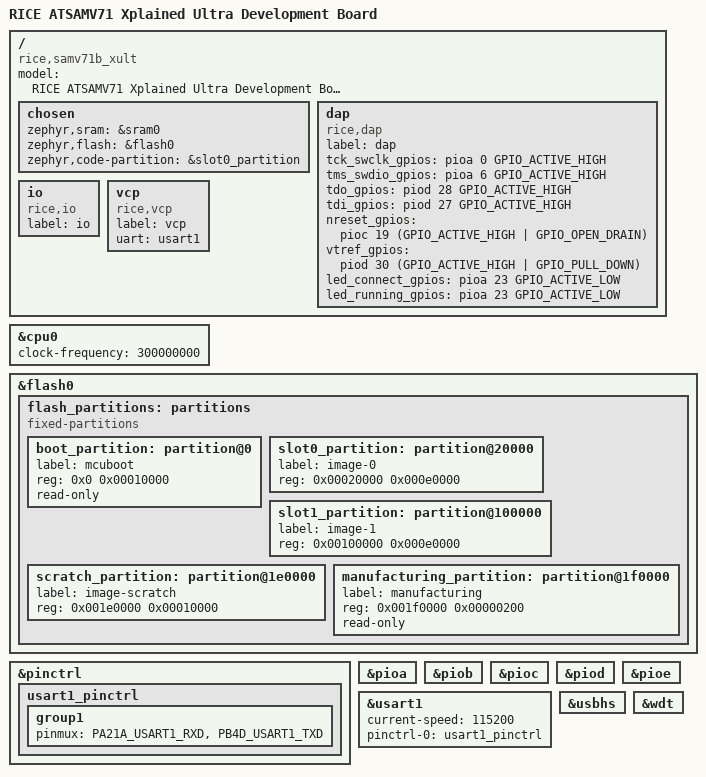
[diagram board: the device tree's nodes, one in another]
/dts-v1/;

#include <atmel/samv71q21b.dtsi>
#include <dt-bindings/pinctrl/samv71q-pinctrl.h>

/ {
    model = "RICE ATSAMV71 Xplained Ultra Development Board";
    compatible = "rice,samv71b_xult", "atmel,samv71q21b", "atmel,samv71b";

    chosen {
		zephyr,sram = &sram0;
		zephyr,flash = &flash0;
		zephyr,code-partition = &slot0_partition;
	};

    dap: dap {
        label = "dap";
        compatible = "rice,dap";

		tck_swclk_gpios = <&pioa 0 GPIO_ACTIVE_HIGH>;
		tms_swdio_gpios = <&pioa 6 GPIO_ACTIVE_HIGH>;
		tdo_gpios = <&piod 28 GPIO_ACTIVE_HIGH>;
		tdi_gpios = <&piod 27 GPIO_ACTIVE_HIGH>;
		nreset_gpios = <&pioc 19 (GPIO_ACTIVE_HIGH | GPIO_OPEN_DRAIN)>;
		vtref_gpios = <&piod 30 (GPIO_ACTIVE_HIGH | GPIO_PULL_DOWN)>;
		led_connect_gpios = <&pioa 23 GPIO_ACTIVE_LOW>;
		led_running_gpios = <&pioa 23 GPIO_ACTIVE_LOW>;
    };

    io: io {
        label = "io";
        compatible = "rice,io";
    };

    vcp: vcp {
        label = "vcp";
        compatible = "rice,vcp";
        uart = <&usart1>;
    };
};

&cpu0 {
	clock-frequency = <300000000>;
};

&flash0 {
	flash_partitions: partitions {
		compatible = "fixed-partitions";
		#address-cells = <1>;
		#size-cells = <1>;

		/* 64 KBytes */
		boot_partition: partition@0 {
			label = "mcuboot";
			reg = <0x0 0x00010000>;
			read-only;
		};

		/* 64 KBytes padding */

		/* 896 KBytes */
		slot0_partition: partition@20000 {
			label = "image-0";
			reg = <0x00020000 0x000e0000>;
		};

		/* 896 KBytes */
		slot1_partition: partition@100000 {
			label = "image-1";
			reg = <0x00100000 0x000e0000>;
		};

		/* 64 KBytes */
		scratch_partition: partition@1e0000 {
			label = "image-scratch";
			reg = <0x001e0000 0x00010000>;
		};

		/* 512 Bytes */
		manufacturing_partition: partition@1f0000 {
			label = "manufacturing";
			reg = <0x001f0000 0x00000200>;
			read-only;
		};
	};
};

&pinctrl {
	usart1_pinctrl: usart1_pinctrl {
		group1 {
			pinmux = <PA21A_USART1_RXD>,
					 <PB4D_USART1_TXD>;
		};
	};
};

&pioa {
	status = "okay";
};

&piob {
	status = "okay";
};

&pioc {
	status = "okay";
};

&piod {
	status = "okay";
};

&pioe {
	status = "okay";
};

&usart1 {
    status = "okay";
	current-speed = <115200>;
    pinctrl-0 = <&usart1_pinctrl>;
	pinctrl-names = "default";
};

usbd: &usbhs {
	status = "okay";
};

&wdt {
	status = "okay";
};
